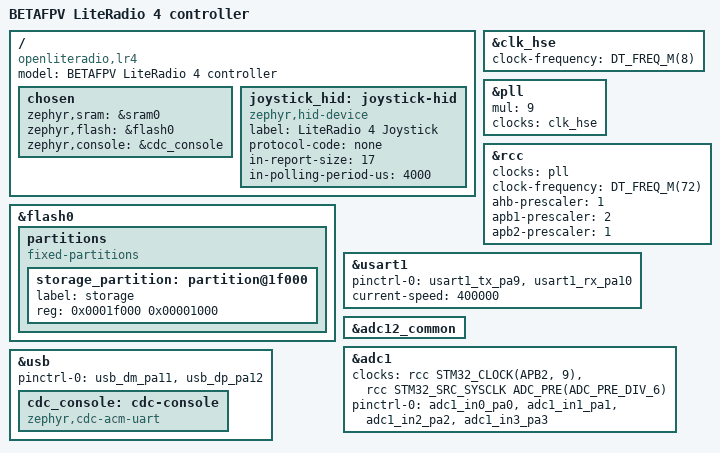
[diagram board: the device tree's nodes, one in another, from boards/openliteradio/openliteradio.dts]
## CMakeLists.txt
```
cmake_minimum_required(VERSION 3.20.0)
list(APPEND BOARD_ROOT ${CMAKE_CURRENT_SOURCE_DIR})
find_package(Zephyr REQUIRED HINTS $ENV{ZEPHYR_BASE})
project(openliteradio)
target_include_directories(app PRIVATE src)
target_sources(app PRIVATE
  src/main.cpp
  src/calibration.cpp
  src/host.cpp
  src/indicators.cpp
  src/module_link.cpp
  src/output.cpp
  src/storage.cpp
  src/battery_monitor.cpp
  src/board/board.cpp
  src/core/battery.cpp
  src/core/channels.cpp
  src/core/crsf.cpp
  src/core/joystick.cpp
  src/core/link_alarm.cpp
  src/core/led.cpp
  src/core/mode.cpp
  src/core/module_command.cpp
  src/core/settings.cpp
  src/core/sound.cpp
  src/core/xbox.cpp
  src/usb_device.c
  src/usb_xinput.c
)
target_sources_ifdef(CONFIG_UPDATER_ENTRY app PRIVATE src/updater_entry.c)
```

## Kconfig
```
config UPDATER_ENTRY
	bool "Enter the vendor USB updater from the application"
	select SOC_EARLY_RESET_HOOK
	help
	  Provide updater_enter(), which restarts into the vendor bootloader's
	  USB update mode without the button combination, and reset out of
	  update mode after a completed download.

source "Kconfig.zephyr"
```

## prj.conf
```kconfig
CONFIG_SIZE_OPTIMIZATIONS=y
CONFIG_GPIO=y
CONFIG_ADC=y
CONFIG_SERIAL=y
CONFIG_UART_INTERRUPT_DRIVEN=y
CONFIG_LOG=n
CONFIG_BOOT_BANNER=n
CONFIG_MAIN_STACK_SIZE=2048
CONFIG_ISR_STACK_SIZE=1024
CONFIG_HEAP_MEM_POOL_SIZE=0
# The vendor bootloader enters the application with interrupts masked (PRIMASK).
CONFIG_INIT_ARCH_HW_AT_BOOT=y
CONFIG_FLASH_LOAD_OFFSET=0x8000
# 0x08008000..0x0801F000; the settings partition follows, see the board's devicetree.
CONFIG_FLASH_LOAD_SIZE=0x17000
CONFIG_BUILD_OUTPUT_BIN=y
# Application logic is C++20; Zephyr builds it without exceptions and RTTI.
CONFIG_CPP=y
CONFIG_STD_CPP20=y
# USB serial port (console and host protocol) and joystick, set up in src/usb_device.c.
CONFIG_USB_DEVICE_STACK_NEXT=y
CONFIG_USBD_CDC_ACM_CLASS=y
CONFIG_CDC_ACM_SERIAL_INITIALIZE_AT_BOOT=n
CONFIG_USBD_HID_SUPPORT=y
# MS OS 2.0 descriptors for the Xbox form of the USB device (src/usb_device.c).
CONFIG_USBD_BOS_SUPPORT=y
CONFIG_CONSOLE=y
CONFIG_UART_CONSOLE=y
CONFIG_UART_LINE_CTRL=y
CONFIG_PRINTK=y
# Restart into the vendor USB updater on request, see src/updater_entry.c.
CONFIG_UPDATER_ENTRY=y
# Settings records in the partition at the top of the application flash.
CONFIG_FLASH=y
CONFIG_FLASH_PAGE_LAYOUT=y
CONFIG_FLASH_MAP=y
CONFIG_NVS=y
```

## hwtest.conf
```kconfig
# Hardware test: console on a USB CDC ACM serial port.
CONFIG_USB_DEVICE_STACK_NEXT=y
CONFIG_USBD_CDC_ACM_CLASS=y
CONFIG_CDC_ACM_SERIAL_INITIALIZE_AT_BOOT=y
CONFIG_CONSOLE=y
CONFIG_UART_CONSOLE=y
CONFIG_UART_LINE_CTRL=y
CONFIG_PRINTK=y
CONFIG_MAIN_STACK_SIZE=2048
CONFIG_UPDATER_ENTRY=y
CONFIG_UART_INTERRUPT_DRIVEN=y
```

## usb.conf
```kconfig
CONFIG_USB_DEVICE_STACK_NEXT=y
CONFIG_USBD_HID_SUPPORT=y
CONFIG_USBD_CDC_ACM_CLASS=y
CONFIG_CDC_ACM_SERIAL_INITIALIZE_AT_BOOT=n
```

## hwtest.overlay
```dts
/ {
    chosen {
        zephyr,console = &cdc_console;
    };
};

zephyr_udc0: &usb {
    pinctrl-0 = <&usb_dm_pa11 &usb_dp_pa12>;
    pinctrl-names = "default";
    status = "okay";
    cdc_console: cdc-console {
        compatible = "zephyr,cdc-acm-uart";
    };
};
```

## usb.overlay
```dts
/ {
    hid_probe: hid-probe {
        compatible = "zephyr,hid-device";
        label = "OpenLiteRadio probe";
        protocol-code = "none";
        in-polling-period-us = <1000>;
        in-report-size = <8>;
    };
};

zephyr_udc0: &usb {
    pinctrl-0 = <&usb_dm_pa11 &usb_dp_pa12>;
    pinctrl-names = "default";
    status = "okay";
    cdc_probe: cdc-probe {
        compatible = "zephyr,cdc-acm-uart";
    };
};
```

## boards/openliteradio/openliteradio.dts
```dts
/dts-v1/;
#include <st/f1/stm32f103Xb.dtsi>
#include <st/f1/stm32f103r(8-b)tx-pinctrl.dtsi>

/ {
    model = "BETAFPV LiteRadio 4 controller";
    compatible = "openliteradio,lr4";
    chosen {
        zephyr,sram = &sram0;
        zephyr,flash = &flash0;
        zephyr,console = &cdc_console;
    };

    /* USB joystick: channels 1 to 8 as axes, 9 to 16 as buttons; see src/core/joystick.h. */
    joystick_hid: joystick-hid {
        compatible = "zephyr,hid-device";
        label = "LiteRadio 4 Joystick";
        protocol-code = "none";
        in-report-size = <17>;
        in-polling-period-us = <4000>;
    };
};

/* 8 MHz crystal, PLL x9, 72 MHz: the configuration the vendor bootloader uses. */
&clk_hse {
    clock-frequency = <DT_FREQ_M(8)>;
    status = "okay";
};

&pll {
    mul = <9>;
    clocks = <&clk_hse>;
    status = "okay";
};

&rcc {
    clocks = <&pll>;
    clock-frequency = <DT_FREQ_M(72)>;
    ahb-prescaler = <1>;
    apb1-prescaler = <2>;
    apb2-prescaler = <1>;
};

/*
 * The last four 1 KiB pages hold the settings. The image ends below them
 * (CONFIG_FLASH_LOAD_SIZE in prj.conf).
 */
&flash0 {
    partitions {
        compatible = "fixed-partitions";
        #address-cells = <1>;
        #size-cells = <1>;

        storage_partition: partition@1f000 {
            label = "storage";
            reg = <0x0001f000 0x00001000>;
        };
    };
};

&usart1 {
    pinctrl-0 = <&usart1_tx_pa9 &usart1_rx_pa10>;
    pinctrl-names = "default";
    current-speed = <400000>;
    status = "okay";
};

/* Common block of ADC1 and ADC2; must be enabled for adc1 to work. */
&adc12_common {
    status = "okay";
};

&adc1 {
    /*
     * ADC prescaler 6: PCLK2 / 6 = 12 MHz, below the 14 MHz ADC limit.
     * The F1 bindings have no PCLK2 source id; SYSCLK equals PCLK2 here.
     */
    clocks = <&rcc STM32_CLOCK(APB2, 9)>,
             <&rcc STM32_SRC_SYSCLK ADC_PRE(ADC_PRE_DIV_6)>;
    clock-names = "adcx", "adc_pre";
    pinctrl-0 = <&adc1_in0_pa0 &adc1_in1_pa1 &adc1_in2_pa2 &adc1_in3_pa3>;
    pinctrl-names = "default";
    status = "okay";
};

/* USB device: a serial port for the console and the host protocol, and the joystick. */
zephyr_udc0: &usb {
    pinctrl-0 = <&usb_dm_pa11 &usb_dp_pa12>;
    pinctrl-names = "default";
    status = "okay";
    cdc_console: cdc-console {
        compatible = "zephyr,cdc-acm-uart";
    };
};
```

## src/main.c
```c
#include <zephyr/kernel.h>
#include <zephyr/drivers/adc.h>
#include <zephyr/drivers/gpio.h>
#include <zephyr/drivers/uart.h>
#include <zephyr/sys/printk.h>
#include <soc.h>

/*
 * Hardware test: reports the loop count, ADC readings and reset flags on the
 * console twice per second. No CRSF frames are sent to the module and no flash
 * is written.
 */

/* Shift register for board control lines, as used by the vendor bootloader. */
#define SHIFT_CLOCK_PIN 12
#define SHIFT_LATCH_PIN 13
#define SHIFT_DATA_PIN  14

/*
 * While this output is high the CH9102 bridge is absent from the USB
 * connector, so the connector is expected to reach this MCU instead. All
 * other outputs stay low.
 */
#define SHIFT_USB_TO_MCU 0x40

/* The ADC is first used after this many loops, so a blocking ADC call shows
 * as console output that stops after ten seconds.
 */
#define ADC_START_LOOP 20

static const struct device *const gpiob = DEVICE_DT_GET(DT_NODELABEL(gpiob));

#ifdef CONFIG_USBD_HID_SUPPORT
int usb_probe_init(void);
#endif

#ifdef CONFIG_UPDATER_ENTRY
void updater_enter(void);

/* Baud rate a host sets on the console port to request update mode. */
#define UPDATER_REQUEST_BAUD 1200
#endif

/* Shift eight bits out, most significant first, then latch them. */
static void shift_write(uint8_t bits)
{
    gpio_pin_set_raw(gpiob, SHIFT_LATCH_PIN, 0);
    for (int bit = 7; bit >= 0; bit--) {
        gpio_pin_set_raw(gpiob, SHIFT_CLOCK_PIN, 0);
        gpio_pin_set_raw(gpiob, SHIFT_DATA_PIN, (bits >> bit) & 1);
        k_busy_wait(50);
        gpio_pin_set_raw(gpiob, SHIFT_CLOCK_PIN, 1);
        k_busy_wait(50);
    }
    gpio_pin_set_raw(gpiob, SHIFT_LATCH_PIN, 1);
}

/* Configure the four stick channels; return 0 or a negative errno. */
static int adc_init(const struct device *adc)
{
    if (!device_is_ready(adc)) {
        return -ENODEV;
    }
    for (uint8_t channel = 0; channel < 4; channel++) {
        struct adc_channel_cfg config = {
            .gain = ADC_GAIN_1,
            .reference = ADC_REF_INTERNAL,
            .acquisition_time = ADC_ACQ_TIME_DEFAULT,
            .channel_id = channel,
        };
        int error = adc_channel_setup(adc, &config);

        if (error < 0) {
            return error;
        }
    }
    return 0;
}

/*
 * Read the four stick channels one at a time; return 0 or a negative errno.
 * Without DMA the STM32F1 ADC driver rejects sequences of several channels.
 */
static int adc_read_axes(const struct device *adc, int16_t samples[4])
{
    for (uint8_t channel = 0; channel < 4; channel++) {
        struct adc_sequence sequence = {
            .channels = BIT(channel),
            .buffer = &samples[channel],
            .buffer_size = sizeof(samples[channel]),
            .resolution = 12,
        };
        int error = adc_read(adc, &sequence);

        if (error < 0) {
            return error;
        }
    }
    return 0;
}

int main(void)
{
    const struct device *adc = DEVICE_DT_GET(DT_NODELABEL(adc1));
    const struct device *uart = DEVICE_DT_GET(DT_NODELABEL(usart1));
    /* Reset flags: bit 29 is set after an independent watchdog reset. */
    uint32_t reset_flags = RCC->CSR;
    int16_t samples[4] = { 0 };
    int adc_status = -EAGAIN;
    uint32_t loops = 0;

#ifdef CONFIG_USBD_HID_SUPPORT
    usb_probe_init();
#endif

    gpio_pin_configure(gpiob, SHIFT_CLOCK_PIN, GPIO_OUTPUT_HIGH);
    gpio_pin_configure(gpiob, SHIFT_LATCH_PIN, GPIO_OUTPUT_HIGH);
    gpio_pin_configure(gpiob, SHIFT_DATA_PIN, GPIO_OUTPUT_LOW);
    shift_write(SHIFT_USB_TO_MCU);

    while (true) {
        if (loops == ADC_START_LOOP) {
            adc_status = adc_init(adc);
        }
        if (adc_status == 0) {
            adc_status = adc_read_axes(adc, samples);
        }
        printk("loops=%u adc=%d axes=%d %d %d %d uart=%d csr=%08x\n",
               loops, adc_status, samples[0], samples[1], samples[2], samples[3],
               device_is_ready(uart), reset_flags);
        loops++;
#ifdef CONFIG_UPDATER_ENTRY
        uint32_t baud = 0;

        uart_line_ctrl_get(DEVICE_DT_GET(DT_CHOSEN(zephyr_console)),
                           UART_LINE_CTRL_BAUD_RATE, &baud);
        if (baud == UPDATER_REQUEST_BAUD) {
            updater_enter();
        }
#endif
        k_msleep(500);
    }
}
```

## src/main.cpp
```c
/*
 * OpenLiteRadio firmware: power handling, controls and indicators, channel
 * frames to the ELRS module, a line protocol on the USB serial port for the
 * configurator in web/, and a USB joystick or Xbox controller.
 *
 * Two threads: the control thread (output.cpp) reads sticks and switches and
 * sends one channel frame per frame period of the module; the main thread
 * (this file) does everything else every 20 ms.
 *
 *   output.cpp       control thread, holds, throttle lock, test inputs
 *   module_link.cpp  frames from the module, link statistics, binding
 *   host.cpp         line protocol to the PC, state lines
 *   storage.cpp      settings in flash
 *   calibration.cpp  stick calibration run
 *   indicators.cpp   buzzer and status LED
 *   battery_monitor.cpp  battery readings and the battery LEDs
 */


#include <zephyr/device.h>
#include <zephyr/drivers/uart.h>
#include <zephyr/kernel.h>
#include <zephyr/sys/printk.h>

#include "battery_monitor.h"
#include "board/board.h"
#include "calibration.h"
#include "core/battery.h"
#include "core/channels.h"
#include "core/link_alarm.h"
#include "core/settings.h"
#include "host.h"
#include "indicators.h"
#include "module_link.h"
#include "output.h"
#include "storage.h"
#include "usb_device.h"

extern "C" void updater_enter(void);

/* Baud rate a host sets on the serial port to request the vendor USB updater. */
constexpr uint32_t UPDATER_REQUEST_BAUD = 1200;

constexpr int LOOP_MS = 20;
constexpr int STATE_EVERY_LOOPS = 2;   /* 25 state lines per second */
constexpr int POWER_ON_LOOPS = battery::ON_HOLD_MS / LOOP_MS;                   /* 1 s */
constexpr int POWER_OFF_LOOPS = (battery::OFF_HOLD_MS + LOOP_MS - 1) / LOOP_MS;  /* 1.25 s */
/* After switching on the battery LEDs stay dark this long, as in the stock firmware. */
constexpr int64_t BAR_AFTER_ON_MS = 500;
constexpr int BIND_HOLD_LOOPS = 50;    /* BIND held for 1 s */
constexpr int SETUP_HOLD_LOOPS = 100;  /* SETUP held for 2 s */
constexpr int USB_SWITCH_LOOPS = 100;  /* both trim centres held for 2 s */
constexpr int TRIM_RESET_LOOPS = 50;   /* a trim centre held for 1 s */

static const struct device *const console = DEVICE_DT_GET(DT_CHOSEN(zephyr_console));

static bool radio_on;
/* The trim was changed with the trim buttons and is not stored yet. */
static bool trim_unsaved;
/* Switched off: the power latch is released once the power-off tune has ended. */
static bool latch_release_pending;
/* Uptime when the radio was switched on. */
static int64_t on_since;
/* The battery LEDs show the link quality instead of the battery; SETUP pressed briefly switches. */
static bool show_link_quality;

static void set_radio_on(bool on)
{
    radio_on = on;
    module_link::set_module_on(on);
    /*
     * Writing to flash holds the output, which locks it, so the trim is only
     * stored here. The power button is still held, which keeps the radio
     * powered until the latch is released.
     */
    if (!on && trim_unsaved) {
        trim_unsaved = !storage::save_trim();
    }
    if (on) {
        board::set_power_latch(true);
    }
    latch_release_pending = !on;
    show_link_quality = false;
    on_since = k_uptime_get();
    indicators::play_event(on ? settings::SOUND_POWER_ON : settings::SOUND_POWER_OFF);
}

/*
 * The USB device's form: only the serial port while the ELRS module is on
 * (radio on, or the host command "module 1"), else the controller chosen in
 * usb.mode. With the module off, both trim centres held for 2 s switch
 * between joystick and Xbox controller and store it. Each change of the
 * form makes the device enumerate again.
 */
static void usb_tick(const board::Inputs &inputs)
{
    static int centres_held_loops;
    static int requested = -1; /* enum usb_function asked for last, -1 before the first */
    bool both = (inputs.trim_left & board::TRIM_CENTRE) && (inputs.trim_right & board::TRIM_CENTRE);
    bool module_on = output::module_is_on();

    if (!module_on && both && !inputs.power) {
        if (++centres_held_loops == USB_SWITCH_LOOPS) {
            settings::set(settings::USB_MODE, settings::values[settings::USB_MODE] == 0 ? 1 : 0);
            storage::save_setting(settings::USB_MODE);
            indicators::play_event(settings::SOUND_ACCEPTED);
        }
    } else {
        centres_held_loops = 0;
    }

    usb_function wanted = module_on ? USB_SERIAL_ONLY
                          : settings::values[settings::USB_MODE] != 0 ? USB_XBOX
                                                                     : USB_JOYSTICK;

    if (wanted != requested) {
        requested = wanted;
        int err = usb_device_select(wanted);

        if (err != 0) {
            /* The device fell back to the serial port only; tell the host and the user. */
            k_msleep(1500);
            printk("error usb %d %d\n", (int)wanted, err);
            indicators::play_event(settings::SOUND_ERROR);
        }
    }
}

/*
 * Trim buttons, one step per press while the radio is on: left button up and
 * down trim the throttle, left and right the yaw; the right button pitch and
 * roll. Each step, also a press beyond the end, gives the tone of sound.trim
 * and the LED flash of trim.led. A centre held for 1 s resets both axes of
 * its button; it counts only once released after switching on, since a
 * centre held at switch-on starts Bluetooth or WiFi.
 */
static void trim_tick(uint8_t left, uint8_t right)
{
    static uint8_t previous_left;
    static uint8_t previous_right;
    static bool centre_armed[2];   /* the centre was released while the radio is on */
    static int centre_held_loops[2];
    const uint8_t buttons[2] = { left, right };
    /* Axes of each button: left throttle and yaw, right pitch and roll. */
    const core::Axis button_axes[2][2] = {
        { core::AXIS_LEFT_VERTICAL, core::AXIS_LEFT_HORIZONTAL },
        { core::AXIS_RIGHT_VERTICAL, core::AXIS_RIGHT_HORIZONTAL },
    };

    for (int side = 0; side < 2; side++) {
        bool held = radio_on && (buttons[side] & board::TRIM_CENTRE);

        if (!held) {
            centre_armed[side] = radio_on;
            centre_held_loops[side] = 0;
        } else if (centre_armed[side] && ++centre_held_loops[side] == TRIM_RESET_LOOPS) {
            centre_armed[side] = false;
            for (core::Axis axis : button_axes[side]) {
                int index = settings::TRIM_FIRST + (int)axis;

                if (settings::values[index] != 0 && settings::set(index, 0)) {
                    trim_unsaved = true;
                }
            }
            indicators::trim_step(1, 0, settings::info(settings::TRIM_FIRST).max);
        }
    }
    uint8_t pressed_left = left & ~previous_left;
    uint8_t pressed_right = right & ~previous_right;
    struct {
        uint8_t pressed; /* newly pressed directions of the button */
        uint8_t plus;    /* direction towards 2012 */
        uint8_t minus;   /* direction towards 988 */
        core::Axis axis;
    } const keys[] = {
        { pressed_left, board::TRIM_UP, board::TRIM_DOWN, core::AXIS_LEFT_VERTICAL },
        { pressed_left, board::TRIM_RIGHT, board::TRIM_LEFT, core::AXIS_LEFT_HORIZONTAL },
        { pressed_right, board::TRIM_UP, board::TRIM_DOWN, core::AXIS_RIGHT_VERTICAL },
        { pressed_right, board::TRIM_RIGHT, board::TRIM_LEFT, core::AXIS_RIGHT_HORIZONTAL },
    };

    previous_left = left;
    previous_right = right;
    if (!radio_on) {
        return;
    }
    for (const auto &key : keys) {
        int step = ((key.pressed & key.plus) ? 1 : 0) - ((key.pressed & key.minus) ? 1 : 0);
        int index = settings::TRIM_FIRST + (int)key.axis;

        if (step == 0) {
            continue;
        }
        int before = settings::values[index];

        /* set() refuses a step beyond the end; the value then stays at the end. */
        if (settings::set(index, before + step)) {
            trim_unsaved = true;
        }
        indicators::trim_step(before, settings::values[index], settings::info(index).max);
    }
}

/*
 * Link to the receiver while the radio sends to one: the tune of
 * sound.connect when a receiver answers, the first time or after a loss, and
 * of sound.lost once when no link statistics came for 1 s. The connect tune
 * waits for a tune still playing, such as the one after a successful binding.
 */
static void link_tick(core::Mode mode)
{
    static link_alarm::State state;
    static bool connect_pending;
    bool active = (mode == core::Mode::ELRS_LOCKED || mode == core::Mode::ELRS_ACTIVE ||
                   mode == core::Mode::ELRS_HOST_READY || mode == core::Mode::ELRS_HOST) &&
                  module_link::starting_task() == core::ModuleTask::NONE;
    link_alarm::Event event = link_alarm::tick(state, active, module_link::receiver_connected());

    if (event == link_alarm::Event::CONNECTED) {
        connect_pending = true;
    } else if (event == link_alarm::Event::LOST || !active) {
        connect_pending = false;
    }
    if (event == link_alarm::Event::LOST) {
        indicators::play_event(settings::SOUND_LINK_LOST);
    } else if (connect_pending && !indicators::playing()) {
        connect_pending = false;
        indicators::play_event(settings::SOUND_CONNECTED);
    }
}

/*
 * Module flashing: the ELRS module on and the USB connector on the CH9102
 * bridge, so that a flasher on the PC reaches the ESP32 directly and puts it
 * into its bootloader with DTR and RTS. Ends only when USB is unplugged.
 */
[[noreturn]] static void module_flashing()
{
    board::set_module_enabled(true);
    board::route_usb_to_module();
    board::set_status_led(0x30, 0x00, 0x18); /* pink */
    while (true) {
        k_sleep(K_FOREVER);
    }
}

int main(void)
{
    output::Snapshot snapshot = {};
    int power_held_loops = 0;
    bool power_handled = false;
    uint32_t loops = 0;
    bool was_locked = true;
    int bind_held_loops = 0;
    int setup_held_loops = 0;

    board::init();
    /* With USB the firmware starts when the cable is plugged in; BIND held then starts module flashing. */
    board::read_controls(snapshot.inputs);
    if (board::usb_supply_present() && snapshot.inputs.bind) {
        module_flashing();
    }
    /*
     * Started from battery by the power button: keep the power on after the
     * button is released, so that a short press can show the battery level
     * before the radio switches off again.
     */
    bool peek_pending = !board::usb_supply_present();
    /* Uptime when the battery level started to blink after a short press; -1 while it does not. */
    int64_t peek_since = -1;

    if (peek_pending) {
        board::set_power_latch(true);
    }
    storage::load_settings();
    host::print_hello();
    output::start();

    while (true) {
        output::snapshot(snapshot);
        board::Inputs &inputs = snapshot.inputs;

        int64_t now = k_uptime_get();
        bool usb = board::usb_supply_present();

        board::read_trims(inputs);
        trim_tick(inputs.trim_left, inputs.trim_right);
        usb_tick(inputs);

        /*
         * Power button: hold 1 s to switch on, 1.25 s to switch off. A shorter
         * press with the radio off shows the battery level, then the latch is
         * released, which on battery switches the radio off again.
         */
        if (inputs.power) {
            power_held_loops++;
            if (!power_handled && !radio_on && power_held_loops >= POWER_ON_LOOPS) {
                set_radio_on(true);
                power_handled = true;
                /* A trim centre held while switching on: left Bluetooth joystick, right WiFi. */
                if (inputs.trim_left & board::TRIM_CENTRE) {
                    module_link::command_start(module_link::COMMAND_BLUETOOTH);
                } else if (inputs.trim_right & board::TRIM_CENTRE) {
                    module_link::command_start(module_link::COMMAND_WIFI);
                }
            } else if (!power_handled && radio_on && power_held_loops >= POWER_OFF_LOOPS) {
                set_radio_on(false);
                power_handled = true;
            }
        } else {
            bool short_press = power_held_loops > 0 && !power_handled;

            if (!radio_on && (short_press || peek_pending)) {
                peek_since = now;
            }
            peek_pending = false;
            power_held_loops = 0;
            power_handled = false;
        }
        if (peek_since >= 0 && now - peek_since >= battery::PEEK_MS) {
            peek_since = -1;
            if (!radio_on && !inputs.power) {
                board::set_power_latch(false);
            }
        }

        /* Battery: a reading every 15 s, the warning on each weak reading while on, the LEDs. */
        if (battery_monitor::tick(now) && radio_on && battery::weak(battery_monitor::raw(), usb)) {
            indicators::weak_battery();
        }
        uint16_t battery_raw = battery_monitor::raw();
        uint8_t bar = battery::bar(battery_raw, usb, (uint32_t)now);
        uint32_t held_ms = (uint32_t)(power_held_loops * LOOP_MS);
        uint8_t battery_leds = 0;

        if (latch_release_pending || (power_handled && !radio_on)) {
            battery_leds = 0; /* switched off; with USB the charge shows again after the tune */
        } else if (inputs.power && !power_handled) {
            battery_leds = radio_on ? battery::switching_off(held_ms, bar) : battery::switching_on(held_ms);
        } else if (peek_since >= 0) {
            battery_leds = battery::peek(battery_raw, (uint32_t)(now - peek_since));
        } else if (radio_on && show_link_quality) {
            battery_leds = battery::link_quality(module_link::receiver_connected(),
                                                 module_link::status().link_quality);
        } else if (battery_raw != 0 && (radio_on ? now - on_since >= BAR_AFTER_ON_MS : usb)) {
            battery_leds = bar;
        }
        battery_monitor::show(battery_leds);

        /* One tune when the throttle lock is released. */
        bool module_is_on = output::module_is_on();

        if (module_is_on && was_locked && !snapshot.locked) {
            indicators::play_event(settings::SOUND_UNLOCK);
        }
        was_locked = snapshot.locked;
        link_tick(snapshot.mode);
        /* While WiFi or Bluetooth waits for the module, the LED shows it already; the output stays locked. */
        core::Mode shown = snapshot.mode;

        if (module_link::starting_task() == core::ModuleTask::WIFI) {
            shown = core::Mode::WIFI;
        } else if (module_link::starting_task() == core::ModuleTask::BLUETOOTH) {
            shown = core::Mode::BLUETOOTH;
        }
        indicators::tick({ shown, calibration::running(), module_link::receiver_connected() });
        /* On battery the radio loses power here unless the power button is still held. */
        if (latch_release_pending && !indicators::playing()) {
            latch_release_pending = false;
            board::set_power_latch(false);
        }

        /* BIND held for 1 s starts binding, a short press ends it. */
        if (inputs.bind) {
            if (++bind_held_loops == BIND_HOLD_LOOPS) {
                module_link::command_start(module_link::COMMAND_BIND);
            }
        } else {
            if (bind_held_loops > 0 && bind_held_loops < BIND_HOLD_LOOPS) {
                module_link::bind_cancel();
            }
            bind_held_loops = 0;
        }

        /*
         * SETUP held for 2 s starts a calibration run, a short press ends it.
         * Otherwise a short press with the radio on switches the battery LEDs
         * between battery and link quality.
         */
        if (calibration::running()) {
            calibration::track(inputs.sticks);
        }
        if (inputs.setup) {
            if (++setup_held_loops == SETUP_HOLD_LOOPS) {
                calibration::start();
            }
        } else {
            bool short_press = setup_held_loops > 0 && setup_held_loops < SETUP_HOLD_LOOPS;

            if (calibration::running() && short_press) {
                calibration::finish(inputs.sticks);
            } else if (radio_on && short_press) {
                show_link_quality = !show_link_quality;
            }
            setup_held_loops = 0;
        }

        module_link::tick();
        host::tick();
        if (host::streaming() && loops % STATE_EVERY_LOOPS == 0) {
            host::print_state(snapshot, radio_on);
        }
        loops++;

        uint32_t baud = 0;

        uart_line_ctrl_get(console, UART_LINE_CTRL_BAUD_RATE, &baud);
        /* Not while the module is on: the restart would cut the link to a model. */
        if (baud == UPDATER_REQUEST_BAUD && !output::module_is_on()) {
            updater_enter();
        }
        k_msleep(LOOP_MS);
    }
}
```

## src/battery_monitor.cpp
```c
#include "battery_monitor.h"

#include "board/board.h"
#include "core/battery.h"

namespace battery_monitor {

namespace {

constexpr int64_t PERIOD_MS = 15000;
constexpr int64_t CHARGER_PAUSE_MS = 100;

uint16_t last_raw;
uint16_t last_vrefint;
/* Internal reference reading with a regulated 3.3 V supply; learned while the battery is high. */
uint16_t vrefint_regulated = battery::VREFINT_DEFAULT;
/* Uptime of the next reading. */
int64_t next_ms;
/* Uptime since which the charger is paused for a reading; -1 while it is not. */
int64_t paused_since = -1;
bool from_host;
/* Mask last sent to the LEDs; 0xff before the first. */
uint8_t shown = 0xff;

/* Read the battery, corrected for a supply below 3.3 V. */
uint16_t read()
{
    uint16_t raw = board::battery_raw();

    last_vrefint = board::vrefint_raw();
    if (raw >= battery::REGULATED_FROM && last_vrefint != 0) {
        vrefint_regulated = last_vrefint;
    }
    return battery::compensate(raw, last_vrefint, vrefint_regulated);
}

} // namespace

bool tick(int64_t now_ms)
{
    if (paused_since >= 0) {
        if (now_ms - paused_since < CHARGER_PAUSE_MS) {
            return false;
        }
        last_raw = read();
        board::set_charger_enabled(true);
        paused_since = -1;
        next_ms = now_ms + PERIOD_MS;
        return true;
    }
    if (now_ms < next_ms) {
        return false;
    }
    if (board::usb_supply_present()) {
        board::set_charger_enabled(false);
        paused_since = now_ms;
        return false;
    }
    last_raw = read();
    next_ms = now_ms + PERIOD_MS;
    return true;
}

uint16_t raw()
{
    return last_raw;
}

uint16_t vrefint()
{
    return last_vrefint;
}

void show(uint8_t mask)
{
    if (!from_host && mask != shown) {
        shown = mask;
        board::set_battery_leds(mask);
    }
}

void set_from_host(bool host, uint8_t mask)
{
    from_host = host;
    shown = 0xff;
    if (host) {
        board::set_battery_leds(mask);
    }
}

} // namespace battery_monitor
```

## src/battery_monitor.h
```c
/* Battery readings every 15 s, and the four battery LEDs. */

#pragma once

#include <stdint.h>

namespace battery_monitor {

/*
 * Call every loop. Takes a reading at the first call and every 15 s after;
 * with USB supply output 0x10 is set low for 100 ms first, as the stock
 * firmware does. Returns true when a new reading was taken.
 */
bool tick(int64_t now_ms);

/*
 * The last reading in raw ADC counts, scaled to a 3.3 V supply with the
 * internal reference (battery::compensate); 0 before the first one.
 */
uint16_t raw();

/* The internal reference's raw reading taken with the last battery reading. */
uint16_t vrefint();

/* Light the battery LEDs (bit 0 leftmost); ignored while the host sets them. */
void show(uint8_t mask);

/* Let the host set the battery LEDs, or give them back to the firmware. */
void set_from_host(bool from_host, uint8_t mask);

} // namespace battery_monitor
```

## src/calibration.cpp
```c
#include "calibration.h"

#include <zephyr/sys/printk.h>
#include <zephyr/sys/util.h>

#include "core/settings.h"
#include "indicators.h"
#include "module_link.h"
#include "output.h"
#include "storage.h"

namespace calibration {

namespace {

bool active;
uint16_t sweep_min[core::AXIS_COUNT];
uint16_t sweep_max[core::AXIS_COUNT];

} // namespace

bool start()
{
    if (active) {
        return true;
    }
    if (module_link::receiver_connected()) {
        indicators::play_event(settings::SOUND_ERROR);
        printk("error receiver connected\n");
        return false;
    }
    for (int axis = 0; axis < core::AXIS_COUNT; axis++) {
        sweep_min[axis] = UINT16_MAX;
        sweep_max[axis] = 0;
    }
    active = true;
    output::set_hold(true);
    indicators::play_event(settings::SOUND_ACCEPTED);
    return true;
}

bool running()
{
    return active;
}

void track(const uint16_t sticks[core::AXIS_COUNT])
{
    for (int axis = 0; axis < core::AXIS_COUNT; axis++) {
        sweep_min[axis] = MIN(sweep_min[axis], sticks[axis]);
        sweep_max[axis] = MAX(sweep_max[axis], sticks[axis]);
    }
}

bool finish(const uint16_t rest[core::AXIS_COUNT])
{
    core::AxisCalibration result[core::AXIS_COUNT];
    bool stored = active;

    for (int axis = 0; axis < core::AXIS_COUNT; axis++) {
        result[axis] = core::calibration_from_sweep(sweep_min[axis], sweep_max[axis], rest[axis],
                                                    axis != core::AXIS_LEFT_VERTICAL);
        stored = stored && core::calibration_valid(result[axis]);
    }
    if (stored) {
        for (int axis = 0; axis < core::AXIS_COUNT; axis++) {
            int16_t *values =
                &settings::values[settings::CALIBRATION_FIRST + settings::CALIBRATION_FIELDS * axis];

            values[0] = (int16_t)result[axis].low;
            values[1] = (int16_t)result[axis].centre;
            values[2] = (int16_t)result[axis].high;
        }
        stored = storage::save_settings();
    }
    active = false;
    output::set_hold(false);
    indicators::play_event(stored ? settings::SOUND_SUCCESS : settings::SOUND_ERROR);
    return stored;
}

void cancel()
{
    active = false;
    output::set_hold(false);
}

} // namespace calibration
```

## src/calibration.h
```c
/*
 * Stick calibration run: started with SETUP held for 2 s or by the host.
 * During the run the sticks are moved to all ends and the module gets safe
 * channel frames. At the end the self-centring axes are released and the
 * throttle is at its lower end.
 */

#pragma once

#include <stdint.h>

#include "core/channels.h"

namespace calibration {

/*
 * Start a run; true if one is running afterwards. Refused while a receiver
 * is connected, with the error tune and the host line "error receiver
 * connected": a run takes the controls away from a model.
 */
bool start();
bool running();

/* Call every loop during a run with the raw stick readings. */
void track(const uint16_t sticks[core::AXIS_COUNT]);

/*
 * End the run. If the result is valid for all axes it goes into the settings
 * cal.N.* and all settings are stored. Returns false otherwise.
 */
bool finish(const uint16_t rest[core::AXIS_COUNT]);

/* End the run and keep the previous calibration. */
void cancel();

} // namespace calibration
```

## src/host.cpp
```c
/*
 * Host protocol on the USB serial port: text lines, one message per line.
 * Every line and command is described in docs/ARCHITECTURE.md, "Host
 * protocol"; that section is the one description, to be changed with the
 * code here.
 */

#include "host.h"

#include <stdlib.h>
#include <string.h>

#include <zephyr/app_version.h>
#include <zephyr/device.h>
#include <zephyr/drivers/uart.h>
#include <zephyr/fatal.h>
#include <zephyr/kernel.h>
#include <zephyr/linker/section_tags.h>
#include <zephyr/sys/printk.h>

#include <cmsis_core.h>
#include <zephyr/sys/util.h>

#include "battery_monitor.h"
#include "board/board.h"
#include "calibration.h"
#include "core/crsf.h"
#include "core/settings.h"
#include "indicators.h"
#include "module_link.h"
#include "storage.h"

namespace host {

namespace {

const struct device *const console = DEVICE_DT_GET(DT_CHOSEN(zephyr_console));

bool stream = true;
/* Next line the "list" command still has to report, settings first, then options; -1 when done. */
int list_next = -1;

/* Keys of "inject", in the order of the output::InjectField bits. */
const char *const INJECT_NAMES[] = { "sticks", "sa", "sb", "sc", "sd", "se", "sf" };

void print_setting(int index)
{
    char key[settings::KEY_SIZE];
    settings::Info info = settings::info(index);

    settings::key(index, key);
    printk("setting %s %s %d %d %d %d\n", key,
           info.options != nullptr ? info.options : (info.min == 0 && info.max == 1) ? "bool" : "int",
           info.min, info.max, info.default_value, settings::values[index]);
}

/*
 * Report a few lines per loop so that the USB buffer keeps up: the settings,
 * then the options, then "end" with the number of lines.
 */
void list_tick()
{
    int lines = settings::COUNT + settings::option_count();

    for (int i = 0; i < 4 && list_next >= 0; i++) {
        if (list_next < settings::COUNT) {
            print_setting(list_next);
        } else {
            settings::Option option = settings::option(list_next - settings::COUNT);

            printk("option %s %d %s\n", option.list, option.value, option.key);
        }
        if (++list_next == lines) {
            printk("end %d\n", lines);
            list_next = -1;
        }
    }
}

/* Run "inject off" or "inject KEY=VALUE ...", with the keys of the state line. */
void handle_inject(char *text)
{
    /* Keys add to the ones still active, so a test can span several short lines. */
    board::Inputs values;
    uint32_t fields;

    output::injection(values, fields);
    for (char *word = strtok(text, " "); word != nullptr; word = strtok(nullptr, " ")) {
        char *value = strchr(word, '=');

        if (strcmp(word, "off") == 0) {
            fields = 0;
            continue;
        }
        if (value == nullptr) {
            printk("error unknown key\n");
            return;
        }
        *value++ = '\0';

        int field = -1;

        for (int i = 0; i < (int)ARRAY_SIZE(INJECT_NAMES); i++) {
            if (strcmp(word, INJECT_NAMES[i]) == 0) {
                field = i;
            }
        }
        long number = strtol(value, &value, 0);

        if (field == 0) {
            values.sticks[0] = (uint16_t)number;
            for (int axis = 1; axis < 4 && *value == ','; axis++) {
                values.sticks[axis] = (uint16_t)strtol(value + 1, &value, 0);
            }
        } else if (field > 0) {
            uint8_t *switches[] = { &values.sa, &values.sb, &values.sc, &values.sd };

            if (field <= 4) {
                *switches[field - 1] = (uint8_t)number;
            } else if (field == 5) {
                values.se = number != 0;
            } else {
                values.sf = number != 0;
            }
        } else {
            printk("error unknown key\n");
            return;
        }
        fields |= BIT(field);
    }
    if (!output::inject(values, fields)) {
        printk("error module on\n");
        return;
    }
    printk("ok inject\n");
}

/* Run one command line from the host. */
void handle_command(char *line)
{
    if (strncmp(line, "inject ", 7) == 0) {
        handle_inject(line + 7);
        return;
    }

    char *arguments[4] = {};
    char *command = strtok(line, " ");

    if (command == nullptr) {
        return;
    }
    for (char *&argument : arguments) {
        argument = strtok(nullptr, " ");
    }
    auto number = [&](int index) {
        return (arguments[index] != nullptr) ? strtol(arguments[index], nullptr, 0) : 0;
    };

    if (strcmp(command, "hello") == 0) {
        print_hello();
    } else if (strcmp(command, "stream") == 0) {
        stream = number(0) != 0;
    } else if (strcmp(command, "led") == 0) {
        indicators::set_led_from_host(arguments[0] != nullptr && strcmp(arguments[0], "auto") != 0,
                                      (uint8_t)number(0), (uint8_t)number(1), (uint8_t)number(2));
    } else if (strcmp(command, "beep") == 0) {
        indicators::beep((uint32_t)number(0), (int)number(1));
    } else if (strcmp(command, "play") == 0) {
        int index = (arguments[0] != nullptr) ? settings::find(arguments[0]) : -1;

        printk(indicators::play_setting(index) ? "ok play\n" : "error unknown key\n");
    } else if (strcmp(command, "batleds") == 0) {
        battery_monitor::set_from_host(arguments[0] != nullptr && strcmp(arguments[0], "auto") != 0,
                                       (uint8_t)number(0));
    } else if (strcmp(command, "module") == 0) {
        module_link::set_module_on(number(0) != 0);
    } else if (strcmp(command, "frames") == 0) {
        module_link::set_show_frames(number(0) != 0);
    } else if (strcmp(command, "crsf") == 0 && arguments[0] != nullptr) {
        /* One complete frame in hex, CRC included, passed to the module unchanged. */
        uint8_t frame[26];
        size_t size = strlen(arguments[0]) / 2;
        bool valid = size >= 4 && size <= sizeof(frame) && strlen(arguments[0]) % 2 == 0;

        for (size_t i = 0; valid && i < size; i++) {
            char pair[3] = { arguments[0][2 * i], arguments[0][2 * i + 1], 0 };
            char *end = nullptr;

            frame[i] = (uint8_t)strtoul(pair, &end, 16);
            valid = end == pair + 2;
        }
        /* Only what reads and writes the module's parameters; channel frames come from the control thread alone. */
        valid = valid && (frame[2] == crsf::TYPE_PING || frame[2] == crsf::TYPE_PARAMETER_READ ||
                          frame[2] == crsf::TYPE_PARAMETER_WRITE);
        printk(valid && output::send_to_module(frame, size) ? "ok crsf\n" : "error crsf\n");
    } else if (strcmp(command, "bind") == 0) {
        module_link::command_start(module_link::COMMAND_BIND);
    } else if (strcmp(command, "wifi") == 0) {
        module_link::command_start(module_link::COMMAND_WIFI);
    } else if (strcmp(command, "ble") == 0) {
        module_link::command_start(module_link::COMMAND_BLUETOOTH);
    } else if (strcmp(command, "list") == 0) {
        list_next = 0;
    } else if (strcmp(command, "get") == 0 || strcmp(command, "set") == 0) {
        int index = (arguments[0] != nullptr) ? settings::find(arguments[0]) : -1;

        if (index < 0) {
            printk("error unknown key\n");
        } else if (command[0] == 'g') {
            printk("value %s %d\n", arguments[0], settings::values[index]);
        } else if (arguments[1] == nullptr || !settings::set(index, number(1))) {
            printk("error value out of range\n");
        } else {
            output::relock();
            /*
             * The USB device changes its form in the next loop and this port
             * goes away with it, before a following "save" may arrive.
             */
            if (index == settings::USB_MODE && !storage::save_setting(index)) {
                printk("error storage\n");
            } else {
                printk("ok %s %d\n", arguments[0], settings::values[index]);
            }
        }
    } else if (strcmp(command, "save") == 0) {
        printk(storage::save_settings() ? "ok save\n" : "error storage\n");
    } else if (strcmp(command, "revert") == 0 || strcmp(command, "defaults") == 0) {
        /* The output locks first, and the control thread never sees half of the change. */
        output::relock();
        int16_t usb_mode = settings::values[settings::USB_MODE];

        k_sched_lock();
        if (command[0] == 'r') {
            storage::load_settings();
        } else {
            /* The stick calibration stays: without it the radio is not usable. */
            for (int index = 0; index < settings::CALIBRATION_FIRST; index++) {
                settings::values[index] = settings::info(index).default_value;
            }
        }
        k_sched_unlock();
        /* As with "set usb.mode": the port goes away with the USB form, before a "save" may arrive. */
        if (command[0] == 'd' && settings::values[settings::USB_MODE] != usb_mode &&
            !storage::save_settings()) {
            printk("error storage\n");
        } else {
            printk("ok %s\n", command);
        }
    } else if (strcmp(command, "calibrate") == 0 && arguments[0] != nullptr) {
        if (strcmp(arguments[0], "start") == 0) {
            /* A refused start has reported its reason already. */
            if (calibration::start()) {
                printk("ok calibrate start\n");
            }
        } else if (strcmp(arguments[0], "end") == 0) {
            output::Snapshot snapshot;

            output::snapshot(snapshot);
            printk(calibration::finish(snapshot.inputs.sticks) ? "ok calibrate end\n"
                                                                : "error calibration rejected\n");
        } else if (strcmp(arguments[0], "cancel") == 0) {
            calibration::cancel();
            printk("ok calibrate cancel\n");
        }
    }
}

/* Collect characters from the host into lines. */
void poll()
{
    static char line[64]; /* "crsf" with a frame of 26 bytes needs 57 characters */
    static size_t length;
    static bool too_long; /* the line did not fit and is not run */
    unsigned char character;

    while (uart_poll_in(console, &character) == 0) {
        if (character == '\n' || character == '\r') {
            if (too_long) {
                printk("error line too long\n");
            } else {
                line[length] = '\0';
                handle_command(line);
            }
            length = 0;
            too_long = false;
        } else if (length < sizeof(line) - 1) {
            line[length++] = (char)character;
        } else {
            too_long = true;
        }
    }
}

} // namespace

/*
 * A fatal error is kept across the restart that follows it and reported once
 * after "hello", so that a crash can be read from the host.
 */
namespace {

constexpr uint32_t FAULT_MARKER = 0x46415554u; /* "FAUT" */
__noinit uint32_t fault_marker;
__noinit uint32_t fault_reason;
__noinit uint32_t fault_pc;
__noinit uint32_t fault_lr;

/* Name and version as one string in the image; the configurator reads it from a firmware file. */
const char IMAGE_ID[] = "OpenLiteRadio " APP_VERSION_STRING;

} // namespace

void print_hello()
{
    /* The protocol number changes with every change of a message; test.ps1 checks web/index.html against it. */
    /* The MCU's 96-bit unique ID, by which the configurator finds this radio again among several. */
    const volatile uint32_t *uid = (const volatile uint32_t *)0x1FFFF7E8;
    printk("hello %s proto=4 id=%08x%08x%08x\n", IMAGE_ID, (unsigned int)uid[0], (unsigned int)uid[1],
           (unsigned int)uid[2]);
    if (fault_marker == FAULT_MARKER) {
        printk("fault reason=%u pc=0x%08x lr=0x%08x\n", (unsigned int)fault_reason,
               (unsigned int)fault_pc, (unsigned int)fault_lr);
        fault_marker = 0;
    }
}

} // namespace host

/* Replaces Zephyr's handler, which halts: keep the cause and restart. */
extern "C" void k_sys_fatal_error_handler(unsigned int reason, const struct arch_esf *esf)
{
    host::fault_reason = reason;
    host::fault_pc = esf != nullptr ? esf->basic.pc : 0;
    host::fault_lr = esf != nullptr ? esf->basic.lr : 0;
    host::fault_marker = host::FAULT_MARKER;
    NVIC_SystemReset();
}

namespace host {

void tick()
{
    poll();
    list_tick();
}

bool streaming()
{
    return stream;
}

void print_state(const output::Snapshot &snapshot, bool radio_on)
{
    const board::Inputs &inputs = snapshot.inputs;
    module_link::Status link = module_link::status();

    printk("state sticks=%u,%u,%u,%u sa=%u sb=%u sc=%u sd=%u se=%u sf=%u bind=%u "
           "setup=%u power=%u tl=%u tr=%u keys=%u battery=%u vref=%u usb=%u on=%u module=%u",
           inputs.sticks[0], inputs.sticks[1], inputs.sticks[2], inputs.sticks[3],
           inputs.sa, inputs.sb, inputs.sc, inputs.sd, inputs.se, inputs.sf,
           inputs.bind, inputs.setup, inputs.power, inputs.trim_left,
           inputs.trim_right, inputs.trims_valid, battery_monitor::raw(), battery_monitor::vrefint(),
           board::usb_supply_present(), radio_on, output::module_is_on());
    const int16_t *trim = &settings::values[settings::TRIM_FIRST];

    printk(" trim=%d,%d,%d,%d ch=", trim[0], trim[1], trim[2], trim[3]);
    for (int channel = 0; channel < core::CHANNEL_COUNT; channel++) {
        printk(channel == 0 ? "%u" : ",%u", snapshot.channels[channel]);
    }
    uint32_t sent = 0;
    uint32_t not_sent = 0;

    output::sent_counts(sent, not_sent);
    printk(" lock=%u period=%u frames=%u crc=%u lq=%u rssi=%u offset=%d bindpar=%u "
           "tx=%u txbusy=%u mode=%s led=%06x calib=%u\n",
           snapshot.locked, (unsigned int)output::frame_period_us(), (unsigned int)link.frames,
           (unsigned int)link.crc_errors, link.link_quality, link.rssi,
           (int)link.timing_offset_us, link.bind_parameter, (unsigned int)sent,
           (unsigned int)not_sent, core::mode_name(snapshot.mode),
           (unsigned int)indicators::led_colour_now(), calibration::running());
}

} // namespace host
```

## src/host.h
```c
/* The line protocol on the USB serial port; described in host.cpp and docs/ARCHITECTURE.md. */

#pragma once

#include "output.h"

namespace host {

void print_hello();

/* Call every loop: run the commands that arrived and continue a "list". */
void tick();

/* Whether the host wants state lines ("stream 0|1"). */
bool streaming();

void print_state(const output::Snapshot &snapshot, bool radio_on);

} // namespace host
```

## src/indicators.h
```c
/* Buzzer and status LED. */

#pragma once

#include <stdint.h>

#include "core/led.h"
#include "core/sound.h"

namespace indicators {

/* Play a tune at the volume in sound.volume; it replaces one still playing. */
void play(const sound::Tune &tune);

/* Play the tune chosen in an event's setting, settings::SOUND_POWER_ON to SOUND_CONNECTED. */
void play_event(int setting);

/*
 * Play what a setting sounds like, for the host command "play": an event's
 * chosen tune, a few trim steps for sound.trim, one beep for sound.volume.
 * Returns false for any other setting.
 */
bool play_setting(int setting);

/* Tone (sound.trim) and LED flash (trim.led) for a trim step from before to value of -limit..limit. */
void trim_step(int before, int value, int limit);

/* Weak battery: the tune in sound.battery and four orange flashes of the status LED. */
void weak_battery();

/* True while a tune is still playing on the buzzer. */
bool playing();

/* One tone at the volume in sound.volume, for the host command "beep". */
void beep(uint32_t frequency, int milliseconds);

/* Let the host set the LED colour, or give it back to the firmware. */
void set_led_from_host(bool from_host, uint8_t red, uint8_t green, uint8_t blue);

/* Call every loop: plays the tunes on and shows the radio's state on the LED (core::led_colour). */
void tick(const core::LedInputs &state);

/* Colour as 0xRRGGBB the LED shows now, also one set by the host. */
uint32_t led_colour_now();

} // namespace indicators
```
